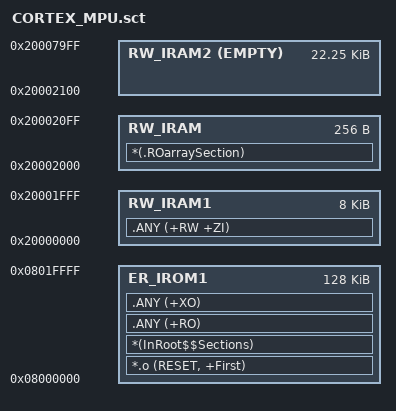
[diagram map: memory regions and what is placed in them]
; *************************************************************
; *** Scatter-Loading Description File generated by uVision ***
; *************************************************************

LR_IROM1 0x08000000 0x00020000  {    ; load region size_region
  ER_IROM1 0x08000000 0x00020000  {  ; load address = execution address
   *.o (RESET, +First)
   *(InRoot$$Sections)
   .ANY (+RO)
   .ANY (+XO)
  }
  RW_IRAM1 0x20000000 0x00002000  {  ; RW data
   .ANY (+RW +ZI)
  }
    RW_IRAM  0x20002000 0x00000100 {
  *(.ROarraySection)
  }
  ; Backup SRAM2
  RW_IRAM2 0x20002100 EMPTY 0x00005900  {  ; to be modified accordingly to user project. Can be NoInit data for backup usage, RW, ZI region, etc...
  }
}

